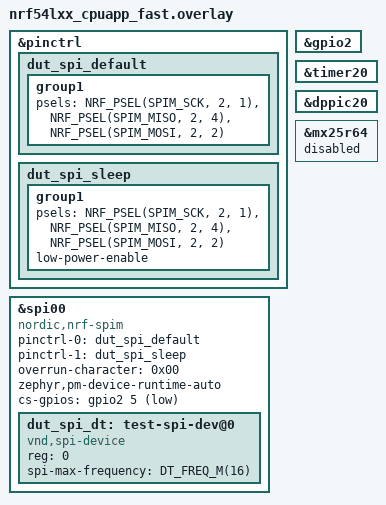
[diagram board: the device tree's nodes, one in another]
/*
 * Copyright (c) 2025 Nordic Semiconductor ASA
 *
 * SPDX-License-Identifier: LicenseRef-Nordic-5-Clause
 */

&pinctrl {
	dut_spi_default: dut_spi_default {
		group1 {
			psels = <NRF_PSEL(SPIM_SCK, 2, 1)>,
				<NRF_PSEL(SPIM_MISO, 2, 4)>,
				<NRF_PSEL(SPIM_MOSI, 2, 2)>;
		};
	};

	dut_spi_sleep: dut_spi_sleep {
		group1 {
			psels = <NRF_PSEL(SPIM_SCK, 2, 1)>,
				<NRF_PSEL(SPIM_MISO, 2, 4)>,
				<NRF_PSEL(SPIM_MOSI, 2, 2)>;
			low-power-enable;
		};
	};
};

dut_spi_fast: &spi00 {
	compatible = "nordic,nrf-spim";
	status = "okay";
	pinctrl-0 = <&dut_spi_default>;
	pinctrl-1 = <&dut_spi_sleep>;
	pinctrl-names = "default", "sleep";
	overrun-character = <0x00>;
	zephyr,pm-device-runtime-auto;
	cs-gpios = <&gpio2 5 GPIO_ACTIVE_LOW>;

	dut_spi_dt: test-spi-dev@0 {
		compatible = "vnd,spi-device";
		reg = <0>;
		spi-max-frequency = <DT_FREQ_M(16)>;
	};
};

&gpio2 {
	status = "okay";
};

tst_timer: &timer20 {
	status = "okay";
};

&dppic20 {
	status = "okay";
};

&mx25r64 {
	status = "disabled";
};
